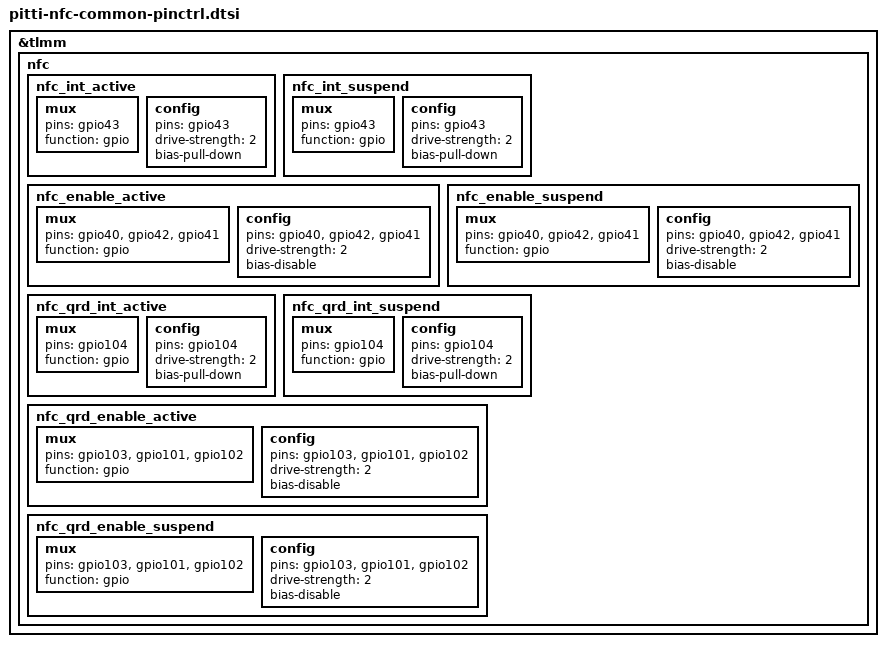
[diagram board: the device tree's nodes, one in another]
&tlmm {
	nfc {
		nfc_int_active: nfc_int_active {
			/* active state */
			mux {
				/* NFC Read Interrupt */
				pins = "gpio43";
				function = "gpio";
			};

			config {
				pins = "gpio43";
				drive-strength = <2>; /* 2 MA */
				bias-pull-down;
			};
		};

		nfc_int_suspend: nfc_int_suspend {
			/* sleep state */
			mux {
				/* NFC Read Interrupt */
				pins = "gpio43";
				function = "gpio";
			};

			config {
				pins = "gpio43";
				drive-strength = <2>; /* 2 MA */
				bias-pull-down;
			};
		};

		nfc_enable_active: nfc_enable_active {
			mux {
				/* Enable, Firmware, clock gpios*/
				pins = "gpio40", "gpio42", "gpio41";
				function = "gpio";
			};

			config {
				pins = "gpio40", "gpio42", "gpio41";
				drive-strength = <2>; /* 2 MA */
				bias-disable;
			};
		};

		nfc_enable_suspend: nfc_enable_suspend {
			mux {
				pins = "gpio40", "gpio42", "gpio41";
				function = "gpio";
			};

			config {
				pins = "gpio40", "gpio42", "gpio41";
				drive-strength = <2>; /* 2 MA */
				bias-disable;
			};
		};
		nfc_qrd_int_active: nfc_qrd_int_active {
			/* active state */
			mux {
				/* NFC Read Interrupt */
				pins = "gpio104";
				function = "gpio";
			};

			config {
				pins = "gpio104";
				drive-strength = <2>; /* 2 MA */
				bias-pull-down;
			};
		};

		nfc_qrd_int_suspend: nfc_qrd_int_suspend {
			/* sleep state */
			mux {
				/* NFC Read Interrupt */
				pins = "gpio104";
				function = "gpio";
			};

			config {
				pins = "gpio104";
				drive-strength = <2>; /* 2 MA */
				bias-pull-down;
			};
		};

		nfc_qrd_enable_active: nfc_qrd_enable_active {
			mux {
				/* Enable, Firmware, clock gpios */
				pins = "gpio103", "gpio101", "gpio102";
				function = "gpio";
			};

			config {
				pins = "gpio103", "gpio101", "gpio102";
				drive-strength = <2>; /* 2 MA */
				bias-disable;
			};
		};

		nfc_qrd_enable_suspend: nfc_qrd_enable_suspend {
			mux {
				pins = "gpio103", "gpio101", "gpio102";
				function = "gpio";
			};

			config {
				pins = "gpio103", "gpio101", "gpio102";
				drive-strength = <2>; /* 2 MA */
				bias-disable;
			};
		};
	}; //nfc
}; //tlmm
